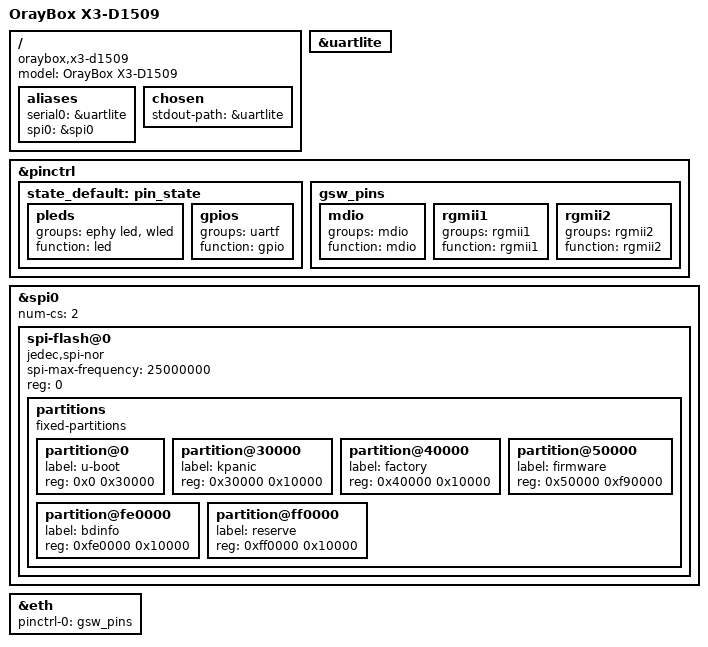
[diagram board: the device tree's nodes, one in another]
// SPDX-License-Identifier: GPL-2.0
/*
 * OrayBox X3-D1509 (MT7620) — 由 oraybox/tools/gen-mtmips-dts.py 自动派生，未上机验证
 *
 * 证据来源: 分区/GPIO 继承 R300/2121G（本板固件无 DTB），未实测
 *   RAM      : 未写明（u-boot 运行时探测）
 *   console  : console=ttyS0,115200
 *   MAC      : bdinfo@0xfe0000 +0x9（同型号借用 X3_3251_5.8.1.dts）
 *   按键/LED : reset=&gpio0 12, wps=&gpio0 10, hc:blue:blue=&gpio0 9, hc:blue:red=&gpio0 7, hc:blue:wifi=&gpio0 8, hc:blue:green=&gpio0 11, hc:blue:link1=&gpio0 0, hc:blue:siginal1=&gpio0 1, hc:blue:siginal2=&gpio0 2, hc:blue:siginal3=&gpio0 3, hc:blue:link2=&gpio0 4
 *
 * 分区表照抄固件 DTB；u-boot 镜像必须小于 u-boot 分区，CI 里有体积守卫。
 */

/dts-v1/;

#include "mt7620.dtsi"

/ {
	compatible = "oraybox,x3-d1509", "mediatek,mt7620-soc";
	model = "OrayBox X3-D1509";

	aliases {
		serial0 = &uartlite;
		spi0 = &spi0;
	};

	chosen {
		stdout-path = &uartlite;
	};
};

&uartlite {
	status = "okay";
};

&pinctrl {
	state_default: pin_state {
		pleds {
			groups = "ephy led", "wled";
			function = "led";
		};

		gpios {
			groups = "uartf";
			function = "gpio";
		};
	};

	/* gsw_pins 在 mainline 里是板级 dts 自己定义的 label（mt7620.dtsi 没有），照 rfb 抄 */
	gsw_pins: gsw_pins {
		mdio {
			groups = "mdio";
			function = "mdio";
		};

		rgmii1 {
			groups = "rgmii1";
			function = "rgmii1";
		};

		rgmii2 {
			groups = "rgmii2";
			function = "rgmii2";
		};
	};
};

&spi0 {
	status = "okay";
		num-cs = <2>;

	spi-flash@0 {
		compatible = "jedec,spi-nor";
		spi-max-frequency = <25000000>;
		reg = <0>;

		partitions {
			compatible = "fixed-partitions";
			#address-cells = <1>;
			#size-cells = <1>;

			partition@0 {
				label = "u-boot";
				reg = <0x0 0x30000>;  /* 只读 */
			};

			partition@30000 {
				label = "kpanic";
				reg = <0x30000 0x10000>;
			};

			partition@40000 {
				label = "factory";
				reg = <0x40000 0x10000>;  /* 只读 */
			};

			partition@50000 {
				label = "firmware";
				reg = <0x50000 0xf90000>;
			};

			partition@fe0000 {
				label = "bdinfo";
				reg = <0xfe0000 0x10000>;
			};

			partition@ff0000 {
				label = "reserve";
				reg = <0xff0000 0x10000>;
			};
		};
	};
};

&eth {
	status = "okay";

	pinctrl-names = "default";
	pinctrl-0 = <&gsw_pins>;
};
